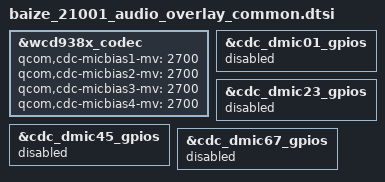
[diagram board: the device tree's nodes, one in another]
/* #ifdef OPLUS_ARCH_EXTENDS */
&wcd938x_codec {
	qcom,cdc-micbias1-mv = <2700>;
	qcom,cdc-micbias2-mv = <2700>;
	qcom,cdc-micbias3-mv = <2700>;
	qcom,cdc-micbias4-mv = <2700>;
};
/* OPLUS_ARCH_EXTENDS */

&cdc_dmic01_gpios {
	status = "disabled";
};

&cdc_dmic23_gpios {
	status = "disabled";
};

&cdc_dmic45_gpios {
	status = "disabled";
};

&cdc_dmic67_gpios {
	status = "disabled";
};
